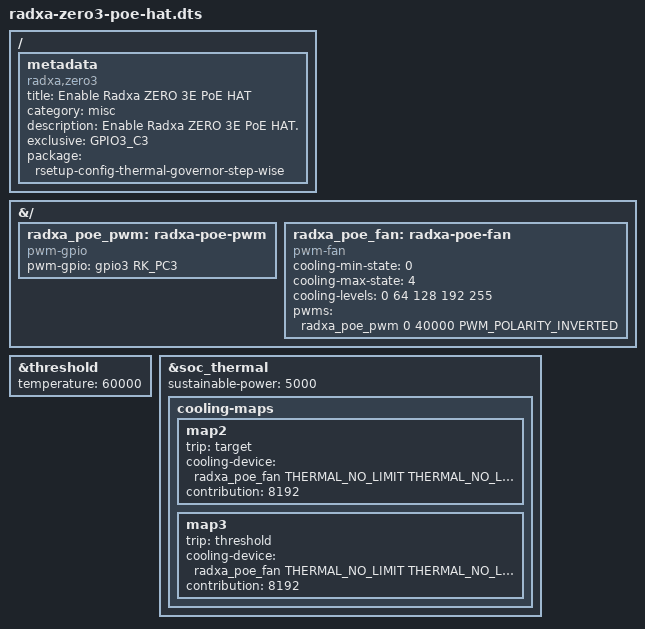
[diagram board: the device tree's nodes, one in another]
/dts-v1/;
/plugin/;

#include <dt-bindings/gpio/gpio.h>
#include <dt-bindings/pinctrl/rockchip.h>
#include <dt-bindings/pwm/pwm.h>
#include <dt-bindings/thermal/thermal.h>

/ {
	metadata {
		title = "Enable Radxa ZERO 3E PoE HAT";
		category = "misc";
		compatible = "radxa,zero3";
		description = "Enable Radxa ZERO 3E PoE HAT.";
		exclusive = "GPIO3_C3";
		package = "rsetup-config-thermal-governor-step-wise";
	};
};

&{/} {
	radxa_poe_pwm: radxa-poe-pwm {
		compatible = "pwm-gpio";
		#pwm-cells = <3>;
		pwm-gpio = <&gpio3 RK_PC3 GPIO_ACTIVE_HIGH>;
	};

	radxa_poe_fan: radxa-poe-fan {
		compatible = "pwm-fan";
		#cooling-cells = <2>;
		cooling-min-state = <0>;
		cooling-max-state = <4>;
		cooling-levels = <0 64 128 192 255>;
		pwms = <&radxa_poe_pwm 0 40000 PWM_POLARITY_INVERTED>;
	};
};

// Radxa ZERO 3E does not have on-board fan header
// Configure the system to support active cooling

&threshold {
	temperature = <60000>;
};

&soc_thermal {
	sustainable-power = <5000>; /* milliwatts */
	cooling-maps {
		map2 {
			trip = <&target>;
			cooling-device = <&radxa_poe_fan THERMAL_NO_LIMIT THERMAL_NO_LIMIT>;
			contribution = <8192>;
		};
		map3 {
			trip = <&threshold>;
			cooling-device = <&radxa_poe_fan THERMAL_NO_LIMIT THERMAL_NO_LIMIT>;
			contribution = <8192>;
		};
	};
};
